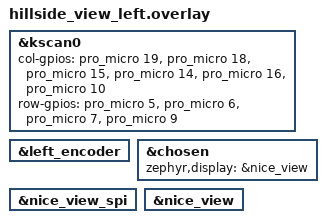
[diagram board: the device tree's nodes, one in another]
/*
 * Copyright (c) 2021-2022 The ZMK Contributors
 *
 * SPDX-License-Identifier: MIT
 */

#include "hillside_view.dtsi" 

&kscan0 {
    col-gpios
        = <&pro_micro 19 GPIO_ACTIVE_HIGH> // col0 in the schematic
        , <&pro_micro 18 GPIO_ACTIVE_HIGH> // col1 in the schematic
        , <&pro_micro 15 GPIO_ACTIVE_HIGH> // col2 in the schematic
        , <&pro_micro 14 GPIO_ACTIVE_HIGH> // col3 in the schematic
        , <&pro_micro 16 GPIO_ACTIVE_HIGH> // col4 in the schematic
        , <&pro_micro 10 GPIO_ACTIVE_HIGH> // col5 in the schematic
        ;
    row-gpios
        = <&pro_micro 5 (GPIO_ACTIVE_HIGH | GPIO_PULL_DOWN)>
        , <&pro_micro 6 (GPIO_ACTIVE_HIGH | GPIO_PULL_DOWN)>
        , <&pro_micro 7 (GPIO_ACTIVE_HIGH | GPIO_PULL_DOWN)>
        , <&pro_micro 9 (GPIO_ACTIVE_HIGH | GPIO_PULL_DOWN)>
        ;
};

&left_encoder {
    status = "okay";
};


&chosen {
  zephyr,display = &nice_view;
};

// nice view bus
&nice_view_spi {
  status = "okay";
};

&nice_view {
  status = "okay";
};
